# Maia SDR register map
Vendor: Daniel Estevez; Series: Maia SDR; File version: 0.6.1
Maia SDR IP core (platform 0)
Registers are 32-bit, read-write, no defined reset value unless marked. A register's access mark holds for its fields unless they carry their own. Offsets are from the block's base; lines under a group give offsets from that group; [hi:lo] are bit positions; {n}, {i} and the like mark numbered series; 'fields as' and 'values as' point back to an identical list; <NAME> marks a mode.

## Memory map
0x00000000 Maia_SDR size 0x44 — Maia SDR IP core (platform 0)

## Maia_SDR — Maia SDR IP core (platform 0)
Base 0x00000000
0x00 product_id ro
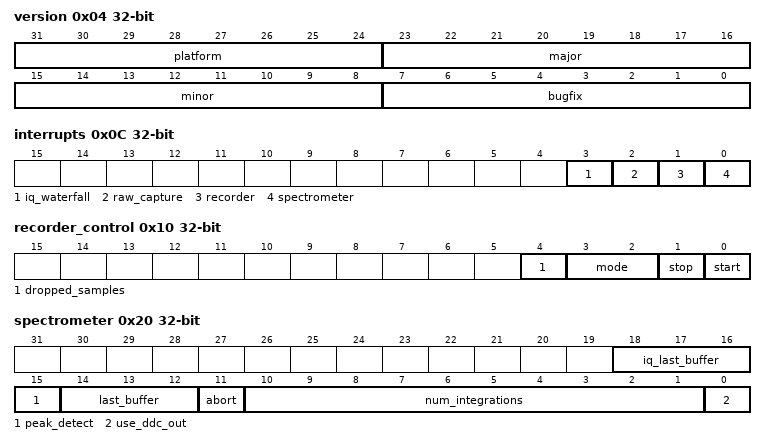
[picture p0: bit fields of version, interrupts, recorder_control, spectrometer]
0x04 version ro
  [31:24] platform, [23:16] major, [15:8] minor, [7:0] bugfix
0x08 control
  [0] sdr_reset
0x0C interrupts ro
  [3] iq_waterfall, [2] raw_capture, [1] recorder, [0] spectrometer
0x10 recorder_control
  [4] dropped_samples ro, [3:2] mode, [1] stop wo, [0] start wo
0x14 recorder_next_address ro
  [31:0] next_address
0x20 spectrometer
  [18:16] iq_last_buffer ro, [15] peak_detect, [14:12] last_buffer ro, [11] abort wo, [10:1] num_integrations, [0] use_ddc_out
0x24 ddc_coeff_addr
  [9:0] coeff_waddr
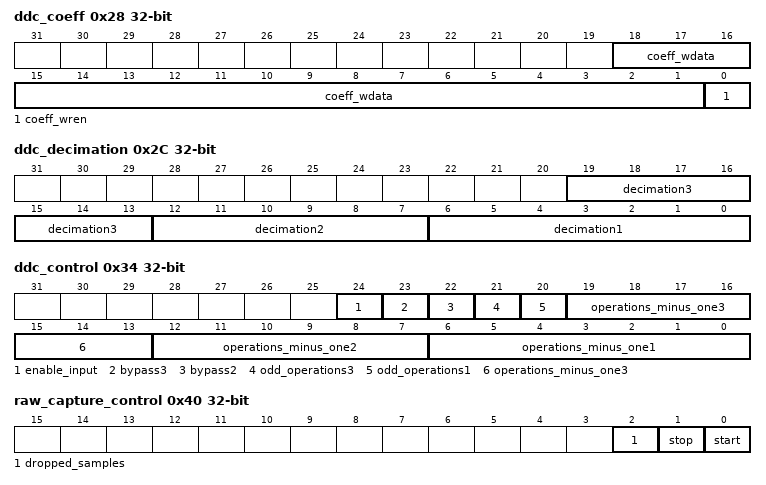
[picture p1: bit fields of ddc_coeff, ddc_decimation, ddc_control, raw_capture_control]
0x28 ddc_coeff
  [18:1] coeff_wdata, [0] coeff_wren wo
0x2C ddc_decimation
  [19:13] decimation3, [12:7] decimation2, [6:0] decimation1
0x30 ddc_frequency
  [27:0] frequency
0x34 ddc_control
  [24] enable_input, [23] bypass3, [22] bypass2, [21] odd_operations3, [20] odd_operations1, [19:13] operations_minus_one3, [12:7] operations_minus_one2, [6:0] operations_minus_one1
0x40 raw_capture_control
  [2] dropped_samples ro, [1] stop wo, [0] start wo
0x44 raw_capture_next_address ro
  [31:0] next_address

## Licence text in the file
SPDX-License-Identifier: MIT Copyright (C) Daniel Estevez 2022-2024
